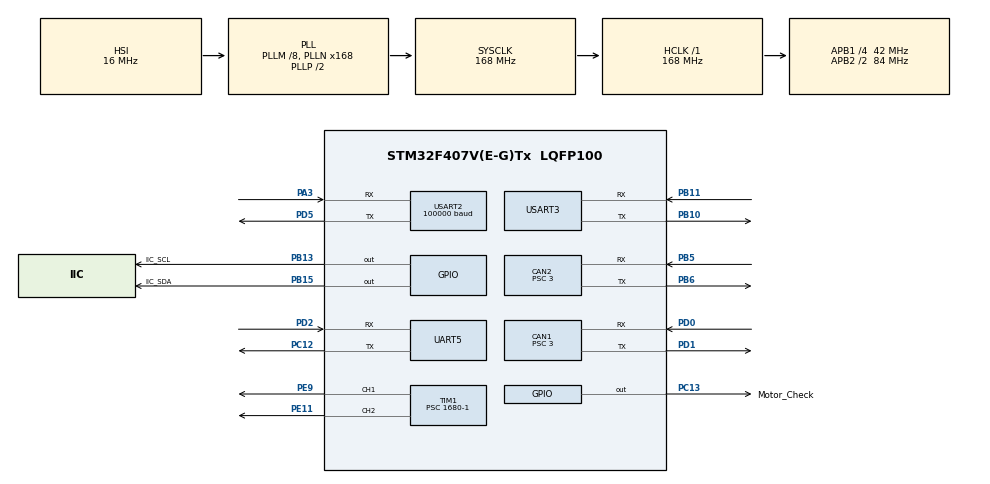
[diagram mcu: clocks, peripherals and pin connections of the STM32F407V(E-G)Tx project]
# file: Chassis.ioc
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CAN1.ABOM=ENABLE
CAN1.BS1=CAN_BS1_9TQ
CAN1.BS2=CAN_BS2_4TQ
CAN1.CalculateBaudRate=1000000
CAN1.CalculateTimeBit=1000
CAN1.CalculateTimeQuantum=71.42857142857143
CAN1.Prescaler=3
CAN1.SJW=CAN_SJW_1TQ
CAN1.TXFP=ENABLE
CAN2.ABOM=ENABLE
CAN2.BS1=CAN_BS1_9TQ
CAN2.BS2=CAN_BS2_4TQ
CAN2.CalculateBaudRate=1000000
CAN2.CalculateTimeBit=1000
CAN2.CalculateTimeQuantum=71.42857142857143
CAN2.Prescaler=3
CAN2.TXFP=ENABLE
Dma.Request0=USART2_RX
Dma.Request1=USART3_RX
Dma.Request2=USART3_TX
Dma.Request3=UART5_RX
Dma.Request4=UART5_TX
Dma.UART5_RX.3.Direction=DMA_PERIPH_TO_MEMORY
Dma.UART5_RX.3.FIFOMode=DMA_FIFOMODE_DISABLE
Dma.UART5_RX.3.Instance=DMA1_Stream0
Dma.UART5_RX.3.MemDataAlignment=DMA_MDATAALIGN_BYTE
Dma.UART5_RX.3.MemInc=DMA_MINC_ENABLE
Dma.UART5_RX.3.Mode=DMA_CIRCULAR
Dma.UART5_RX.3.PeriphDataAlignment=DMA_PDATAALIGN_BYTE
Dma.UART5_RX.3.PeriphInc=DMA_PINC_DISABLE
Dma.UART5_RX.3.Priority=DMA_PRIORITY_VERY_HIGH
Dma.UART5_TX.4.Direction=DMA_MEMORY_TO_PERIPH
Dma.UART5_TX.4.FIFOMode=DMA_FIFOMODE_DISABLE
Dma.UART5_TX.4.Instance=DMA1_Stream7
Dma.UART5_TX.4.MemDataAlignment=DMA_MDATAALIGN_BYTE
Dma.UART5_TX.4.MemInc=DMA_MINC_ENABLE
Dma.UART5_TX.4.Mode=DMA_NORMAL
Dma.UART5_TX.4.PeriphDataAlignment=DMA_PDATAALIGN_BYTE
Dma.UART5_TX.4.PeriphInc=DMA_PINC_DISABLE
Dma.UART5_TX.4.Priority=DMA_PRIORITY_VERY_HIGH
Dma.USART2_RX.0.Direction=DMA_PERIPH_TO_MEMORY
Dma.USART2_RX.0.FIFOMode=DMA_FIFOMODE_DISABLE
Dma.USART2_RX.0.Instance=DMA1_Stream5
Dma.USART2_RX.0.MemDataAlignment=DMA_MDATAALIGN_BYTE
Dma.USART2_RX.0.MemInc=DMA_MINC_ENABLE
Dma.USART2_RX.0.Mode=DMA_NORMAL
Dma.USART2_RX.0.PeriphDataAlignment=DMA_PDATAALIGN_BYTE
Dma.USART2_RX.0.PeriphInc=DMA_PINC_DISABLE
Dma.USART2_RX.0.Priority=DMA_PRIORITY_VERY_HIGH
Dma.USART3_RX.1.Direction=DMA_PERIPH_TO_MEMORY
Dma.USART3_RX.1.FIFOMode=DMA_FIFOMODE_DISABLE
Dma.USART3_RX.1.Instance=DMA1_Stream1
Dma.USART3_RX.1.MemDataAlignment=DMA_MDATAALIGN_BYTE
Dma.USART3_RX.1.MemInc=DMA_MINC_ENABLE
Dma.USART3_RX.1.Mode=DMA_CIRCULAR
Dma.USART3_RX.1.PeriphDataAlignment=DMA_PDATAALIGN_BYTE
Dma.USART3_RX.1.PeriphInc=DMA_PINC_DISABLE
Dma.USART3_RX.1.Priority=DMA_PRIORITY_HIGH
Dma.USART3_TX.2.Direction=DMA_MEMORY_TO_PERIPH
Dma.USART3_TX.2.FIFOMode=DMA_FIFOMODE_DISABLE
Dma.USART3_TX.2.Instance=DMA1_Stream3
Dma.USART3_TX.2.MemDataAlignment=DMA_MDATAALIGN_BYTE
Dma.USART3_TX.2.MemInc=DMA_MINC_ENABLE
Dma.USART3_TX.2.Mode=DMA_NORMAL
Dma.USART3_TX.2.PeriphDataAlignment=DMA_PDATAALIGN_BYTE
Dma.USART3_TX.2.PeriphInc=DMA_PINC_DISABLE
Dma.USART3_TX.2.Priority=DMA_PRIORITY_HIGH
FREERTOS.Tasks01=defaultTask,0,128,StartDefaultTask,Default,NULL,Dynamic,NULL,NULL;Chassis_Task,0,128,StartChassis_Task,As weak,NULL,Dynamic,NULL,NULL;WorkStateTask,0,128,StartWorkStateTask,As weak,NULL,Dynamic,NULL,NULL;ImuTask,1,128,StartImuTask,As weak,NULL,Dynamic,NULL,NULL;RC_HeartTask,1,128,StartRC_HeartTask,As weak,NULL,Dynamic,NULL,NULL;RC_DialTask,1,128,StartRC_DialTask,As weak,NULL,Dynamic,NULL,NULL;Shoot_Task,0,128,StartShoot_Task,As weak,NULL,Dynamic,NULL,NULL;Gimbal_Task,0,128,StartGimbal_Task,As weak,NULL,Dynamic,NULL,NULL;Vision_Task,0,128,StartVision_Task,As weak,NULL,Dynamic,NULL,NULL;Judge_Task,0,128,StartJudge_Task,As weak,NULL,Dynamic,NULL,NULL
Mcu.Family=STM32F4
Mcu.Name=STM32F407V(E-G)Tx
Mcu.Package=LQFP100
NVIC.CAN1_RX0_IRQn=true\:5\:0\:false\:false\:true\:true\:true\:true
NVIC.CAN2_RX0_IRQn=true\:5\:0\:false\:false\:true\:true\:true\:true
NVIC.DMA1_Stream0_IRQn=true\:5\:0\:false\:false\:true\:true\:false\:true
NVIC.DMA1_Stream1_IRQn=true\:5\:0\:false\:false\:true\:true\:false\:true
NVIC.DMA1_Stream3_IRQn=true\:5\:0\:false\:false\:true\:true\:false\:true
NVIC.DMA1_Stream5_IRQn=true\:5\:0\:false\:false\:true\:true\:false\:true
NVIC.DMA1_Stream7_IRQn=true\:5\:0\:false\:false\:true\:true\:false\:true
NVIC.PriorityGroup=NVIC_PRIORITYGROUP_4
NVIC.TIM2_IRQn=true\:15\:0\:false\:false\:true\:false\:false\:true
NVIC.TimeBase=TIM2_IRQn
NVIC.TimeBaseIP=TIM2
NVIC.UART5_IRQn=true\:5\:0\:false\:false\:true\:true\:true\:true
NVIC.USART2_IRQn=true\:5\:0\:false\:false\:true\:true\:true\:true
NVIC.USART3_IRQn=true\:5\:0\:false\:false\:true\:true\:true\:true
PA13.Mode=Serial_Wire
PA13.Signal=SYS_JTMS-SWDIO
PA14.Mode=Serial_Wire
PA14.Signal=SYS_JTCK-SWCLK
PA3.Mode=Asynchronous
PA3.Signal=USART2_RX
PB10.Mode=Asynchronous
PB10.Signal=USART3_TX
PB11.Mode=Asynchronous
PB11.Signal=USART3_RX
PB13.GPIO_Label=IIC_SCL
PB13.GPIO_Speed=GPIO_SPEED_FREQ_VERY_HIGH
PB13.PinState=GPIO_PIN_SET
PB13.Signal=GPIO_Output
PB15.GPIO_Label=IIC_SDA
PB15.GPIO_Speed=GPIO_SPEED_FREQ_VERY_HIGH
PB15.PinState=GPIO_PIN_SET
PB15.Signal=GPIO_Output
PB5.Mode=CAN_Activate
PB5.Signal=CAN2_RX
PB6.Mode=CAN_Activate
PB6.Signal=CAN2_TX
PC12.Mode=Asynchronous
PC12.Signal=UART5_TX
PC13-ANTI_TAMP.GPIO_Label=Motor_Check
PC13-ANTI_TAMP.PinState=GPIO_PIN_SET
PC13-ANTI_TAMP.Signal=GPIO_Output
PC14-OSC32_IN.Mode=LSE-External-Oscillator
PC14-OSC32_IN.Signal=RCC_OSC32_IN
PC15-OSC32_OUT.Mode=LSE-External-Oscillator
PC15-OSC32_OUT.Signal=RCC_OSC32_OUT
PD0.Mode=CAN_Activate
PD0.Signal=CAN1_RX
PD1.Mode=CAN_Activate
PD1.Signal=CAN1_TX
PD2.Mode=Asynchronous
PD2.Signal=UART5_RX
PD5.Mode=Asynchronous
PD5.Signal=USART2_TX
PE11.Signal=S_TIM1_CH2
PE9.Signal=S_TIM1_CH1
PH0-OSC_IN.Mode=HSE-External-Oscillator
PH0-OSC_IN.Signal=RCC_OSC_IN
PH1-OSC_OUT.Mode=HSE-External-Oscillator
PH1-OSC_OUT.Signal=RCC_OSC_OUT
ProjectManager.HeapSize=0x200
ProjectManager.StackSize=0x400
ProjectManager.TargetToolchain=MDK-ARM V5.32
RCC.48MHZClocksFreq_Value=84000000
RCC.AHBFreq_Value=168000000
RCC.APB1CLKDivider=RCC_HCLK_DIV4
RCC.APB1Freq_Value=42000000
RCC.APB1TimFreq_Value=84000000
RCC.APB2CLKDivider=RCC_HCLK_DIV2
RCC.APB2Freq_Value=84000000
RCC.APB2TimFreq_Value=168000000
RCC.CortexFreq_Value=168000000
RCC.HCLKFreq_Value=168000000
RCC.HSE_VALUE=25000000
RCC.HSI_VALUE=16000000
RCC.PLLM=8
RCC.PLLN=168
RCC.SYSCLKFreq_VALUE=168000000
RCC.SYSCLKSource=RCC_SYSCLKSOURCE_PLLCLK
RCC.VCOOutputFreq_Value=336000000
SH.S_TIM1_CH1.0=TIM1_CH1,PWM Generation1 CH1
SH.S_TIM1_CH2.0=TIM1_CH2,PWM Generation2 CH2
TIM1.Channel-PWM\ Generation1\ CH1=TIM_CHANNEL_1
TIM1.Channel-PWM\ Generation2\ CH2=TIM_CHANNEL_2
TIM1.Period=1000-1
TIM1.Prescaler=1680-1
UART5.VirtualMode=Asynchronous
USART2.BaudRate=100000
USART2.VirtualMode=VM_ASYNC
USART3.VirtualMode=VM_ASYNC
VP_FREERTOS_VS_CMSIS_V1.Mode=CMSIS_V1
VP_SYS_VS_tim2.Mode=TIM2
VP_TIM1_VS_ClockSourceINT.Mode=Internal
board=custom

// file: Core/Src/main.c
/* USER CODE BEGIN Header */
/**
  ******************************************************************************
  * @file           : main.c
  * @brief          : Main program body
  ******************************************************************************
  * @attention
  *
  * Copyright (c) 2022 STMicroelectronics.
  * All rights reserved.
  *
  * This software is licensed under terms that can be found in the LICENSE file
  * in the root directory of this software component.
  * If no LICENSE file comes with this software, it is provided AS-IS.
  *
  ******************************************************************************
  */
/* USER CODE END Header */
#include "main.h"
#include "cmsis_os.h"
#include "can.h"
#include "dma.h"
#include "tim.h"
#include "usart.h"
#include "gpio.h"

/* USER CODE BEGIN Includes */
#include "drv_uart.h"
#include "usart.h"
#include "drv_can.h"
/* USER CODE END Includes */

void SystemClock_Config(void);
void MX_FREERTOS_Init(void);

int main(void)
{

  /* MCU Configuration--------------------------------------------------------*/

  /* Reset of all peripherals, Initializes the Flash interface and the Systick. */
  HAL_Init();

  /* Configure the system clock */
  SystemClock_Config();

  /* Initialize all configured peripherals */
  MX_GPIO_Init();
  MX_CAN1_Init();
  MX_DMA_Init();
  MX_USART2_UART_Init();
  MX_CAN2_Init();
  MX_TIM1_Init();
  MX_USART3_UART_Init();
  MX_UART5_Init();
  /* USER CODE BEGIN 2 */

	//-----------ң����------------//
	HAL_UART_MspInit(&huart2);
	USART2_Init();

	//-----------�Ӿ�------------//
	HAL_UART_MspInit(&huart3);
	USART3_Init();

	//----------����ϵͳ------------//
	HAL_UART_MspInit(&huart5);
	USART5_Init();

	//----------CAN1��CAN2-------------//
	CAN_Init();

  /* USER CODE END 2 */

  /* Call init function for freertos objects (in freertos.c) */
  MX_FREERTOS_Init();
  /* Start scheduler */
  osKernelStart();

  /* We should never get here as control is now taken by the scheduler */
  /* Infinite loop */
  while (1)
  {

  }
}

void SystemClock_Config(void)
{
  RCC_OscInitTypeDef RCC_OscInitStruct = {0};
  RCC_ClkInitTypeDef RCC_ClkInitStruct = {0};

  /** Configure the main internal regulator output voltage
  */
  __HAL_RCC_PWR_CLK_ENABLE();
  __HAL_PWR_VOLTAGESCALING_CONFIG(PWR_REGULATOR_VOLTAGE_SCALE1);
  /** Initializes the RCC Oscillators according to the specified parameters
  * in the RCC_OscInitTypeDef structure.
  */
  RCC_OscInitStruct.OscillatorType = RCC_OSCILLATORTYPE_HSI;
  RCC_OscInitStruct.HSIState = RCC_HSI_ON;
  RCC_OscInitStruct.HSICalibrationValue = RCC_HSICALIBRATION_DEFAULT;
  RCC_OscInitStruct.PLL.PLLState = RCC_PLL_ON;
  RCC_OscInitStruct.PLL.PLLSource = RCC_PLLSOURCE_HSI;
  RCC_OscInitStruct.PLL.PLLM = 8;
  RCC_OscInitStruct.PLL.PLLN = 168;
  RCC_OscInitStruct.PLL.PLLP = RCC_PLLP_DIV2;
  RCC_OscInitStruct.PLL.PLLQ = 4;
  if (HAL_RCC_OscConfig(&RCC_OscInitStruct) != HAL_OK)
  {
    Error_Handler();
  }
  /** Initializes the CPU, AHB and APB buses clocks
  */
  RCC_ClkInitStruct.ClockType = RCC_CLOCKTYPE_HCLK|RCC_CLOCKTYPE_SYSCLK
                              |RCC_CLOCKTYPE_PCLK1|RCC_CLOCKTYPE_PCLK2;
  RCC_ClkInitStruct.SYSCLKSource = RCC_SYSCLKSOURCE_PLLCLK;
  RCC_ClkInitStruct.AHBCLKDivider = RCC_SYSCLK_DIV1;
  RCC_ClkInitStruct.APB1CLKDivider = RCC_HCLK_DIV4;
  RCC_ClkInitStruct.APB2CLKDivider = RCC_HCLK_DIV2;

  if (HAL_RCC_ClockConfig(&RCC_ClkInitStruct, FLASH_LATENCY_5) != HAL_OK)
  {
    Error_Handler();
  }
}

void HAL_TIM_PeriodElapsedCallback(TIM_HandleTypeDef *htim)
{
  if (htim->Instance == TIM2) {
    HAL_IncTick();
  }
}

void Error_Handler(void)
{
  __disable_irq();
  while (1)
  {
  }
}

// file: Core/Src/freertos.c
/* USER CODE BEGIN Header */
/**
  ******************************************************************************
  * File Name          : freertos.c
  * Description        : Code for freertos applications
  ******************************************************************************
  * @attention
  *
  * Copyright (c) 2022 STMicroelectronics.
  * All rights reserved.
  *
  * This software is licensed under terms that can be found in the LICENSE file
  * in the root directory of this software component.
  * If no LICENSE file comes with this software, it is provided AS-IS.
  *
  ******************************************************************************
  */
/* USER CODE END Header */

#include "FreeRTOS.h"
#include "task.h"
#include "main.h"
#include "cmsis_os.h"

osThreadId defaultTaskHandle;
osThreadId Chassis_TaskHandle;
osThreadId WorkStateTaskHandle;
osThreadId ImuTaskHandle;
osThreadId RC_HeartTaskHandle;
osThreadId RC_DialTaskHandle;
osThreadId Shoot_TaskHandle;
osThreadId Gimbal_TaskHandle;
osThreadId Vision_TaskHandle;
osThreadId Judge_TaskHandle;

void StartDefaultTask(void const * argument);
void StartChassis_Task(void const * argument);
void StartWorkStateTask(void const * argument);
void StartImuTask(void const * argument);
void StartRC_HeartTask(void const * argument);
void StartRC_DialTask(void const * argument);
void StartShoot_Task(void const * argument);
void StartGimbal_Task(void const * argument);
void StartVision_Task(void const * argument);
void StartJudge_Task(void const * argument);

void MX_FREERTOS_Init(void); /* (MISRA C 2004 rule 8.1) */

/* GetIdleTaskMemory prototype (linked to static allocation support) */
void vApplicationGetIdleTaskMemory( StaticTask_t **ppxIdleTaskTCBBuffer, StackType_t **ppxIdleTaskStackBuffer, uint32_t *pulIdleTaskStackSize );

/* USER CODE BEGIN GET_IDLE_TASK_MEMORY */
static StaticTask_t xIdleTaskTCBBuffer;
static StackType_t xIdleStack[configMINIMAL_STACK_SIZE];

void vApplicationGetIdleTaskMemory( StaticTask_t **ppxIdleTaskTCBBuffer, StackType_t **ppxIdleTaskStackBuffer, uint32_t *pulIdleTaskStackSize )
{
  *ppxIdleTaskTCBBuffer = &xIdleTaskTCBBuffer;
  *ppxIdleTaskStackBuffer = &xIdleStack[0];
  *pulIdleTaskStackSize = configMINIMAL_STACK_SIZE;
  /* place for user code */
}
/* USER CODE END GET_IDLE_TASK_MEMORY */

void MX_FREERTOS_Init(void) {

  /* Create the thread(s) */
  /* definition and creation of defaultTask */
  osThreadDef(defaultTask, StartDefaultTask, osPriorityNormal, 0, 128);
  defaultTaskHandle = osThreadCreate(osThread(defaultTask), NULL);

  /* definition and creation of Chassis_Task */
  osThreadDef(Chassis_Task, StartChassis_Task, osPriorityNormal, 0, 128);
  Chassis_TaskHandle = osThreadCreate(osThread(Chassis_Task), NULL);

  /* definition and creation of WorkStateTask */
  osThreadDef(WorkStateTask, StartWorkStateTask, osPriorityNormal, 0, 128);
  WorkStateTaskHandle = osThreadCreate(osThread(WorkStateTask), NULL);

  /* definition and creation of ImuTask */
  osThreadDef(ImuTask, StartImuTask, osPriorityAboveNormal, 0, 128);
  ImuTaskHandle = osThreadCreate(osThread(ImuTask), NULL);

  /* definition and creation of RC_HeartTask */
  osThreadDef(RC_HeartTask, StartRC_HeartTask, osPriorityAboveNormal, 0, 128);
  RC_HeartTaskHandle = osThreadCreate(osThread(RC_HeartTask), NULL);

  /* definition and creation of RC_DialTask */
  osThreadDef(RC_DialTask, StartRC_DialTask, osPriorityAboveNormal, 0, 128);
  RC_DialTaskHandle = osThreadCreate(osThread(RC_DialTask), NULL);

  /* definition and creation of Shoot_Task */
  osThreadDef(Shoot_Task, StartShoot_Task, osPriorityNormal, 0, 128);
  Shoot_TaskHandle = osThreadCreate(osThread(Shoot_Task), NULL);

  /* definition and creation of Gimbal_Task */
  osThreadDef(Gimbal_Task, StartGimbal_Task, osPriorityNormal, 0, 128);
  Gimbal_TaskHandle = osThreadCreate(osThread(Gimbal_Task), NULL);

  /* definition and creation of Vision_Task */
  osThreadDef(Vision_Task, StartVision_Task, osPriorityNormal, 0, 128);
  Vision_TaskHandle = osThreadCreate(osThread(Vision_Task), NULL);

  /* definition and creation of Judge_Task */
  osThreadDef(Judge_Task, StartJudge_Task, osPriorityNormal, 0, 128);
  Judge_TaskHandle = osThreadCreate(osThread(Judge_Task), NULL);

}

void StartDefaultTask(void const * argument)
{
  for(;;)
  {
    osDelay(1);
  }
}

__weak void StartChassis_Task(void const * argument)
{
  for(;;)
  {
    osDelay(1);
  }
}

__weak void StartWorkStateTask(void const * argument)
{
  for(;;)
  {
    osDelay(1);
  }
}

__weak void StartImuTask(void const * argument)
{
  for(;;)
  {
    osDelay(1);
  }
}

__weak void StartRC_HeartTask(void const * argument)
{
  for(;;)
  {
    osDelay(1);
  }
}

__weak void StartRC_DialTask(void const * argument)
{
  for(;;)
  {
    osDelay(1);
  }
}

__weak void StartShoot_Task(void const * argument)
{
  for(;;)
  {
    osDelay(1);
  }
}

__weak void StartGimbal_Task(void const * argument)
{
  for(;;)
  {
    osDelay(1);
  }
}

__weak void StartVision_Task(void const * argument)
{
  for(;;)
  {
    osDelay(1);
  }
}

__weak void StartJudge_Task(void const * argument)
{
  for(;;)
  {
    osDelay(1);
  }
}
